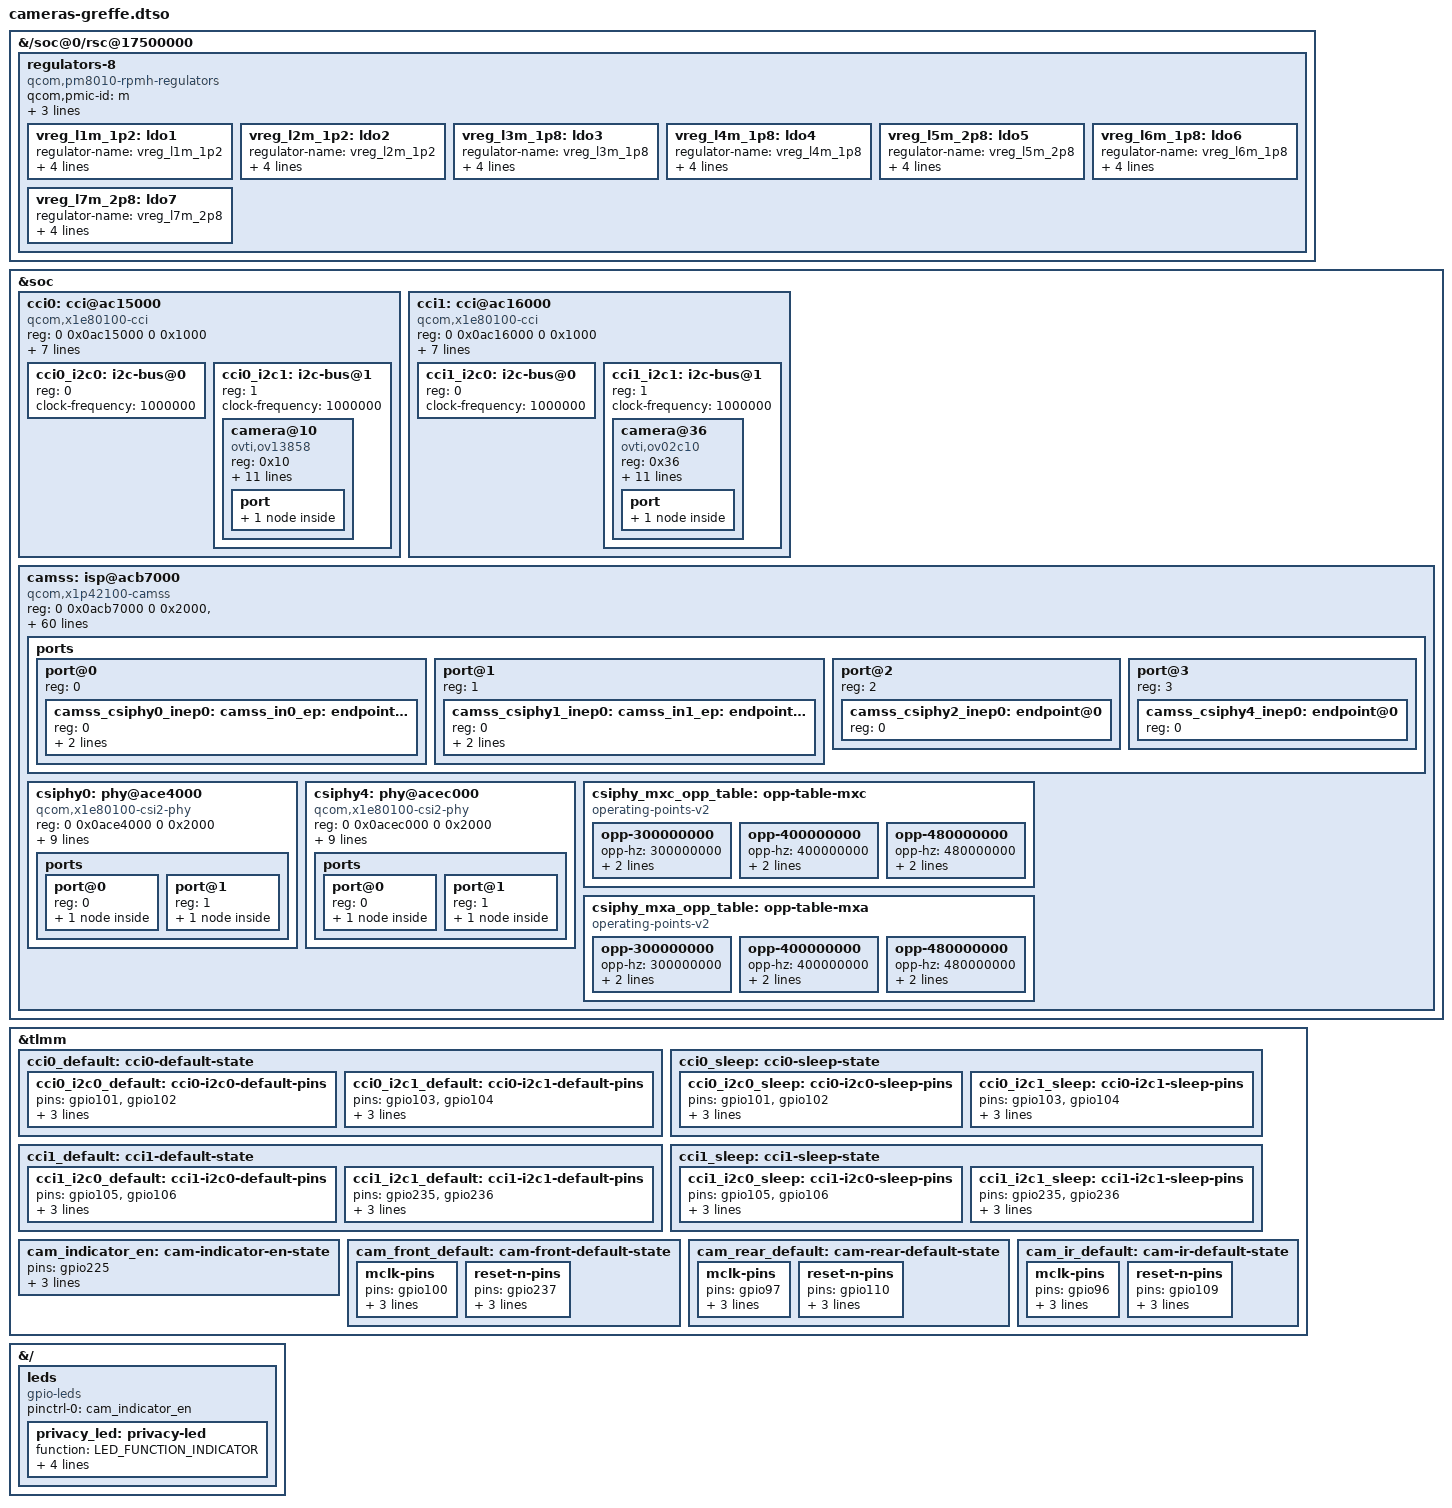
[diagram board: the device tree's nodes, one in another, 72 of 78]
/dts-v1/;
/plugin/;

/* Greffe caméra pour le DTB de juin (sp12-el2-pdc-test.dtb).
 * Fabriqué par systeme/bin/greffer-cameras.js — ne pas éditer à la main.
 * Les blocs sont découpés dans hamoa.dtsi et x1p42100-microsoft-sp12in.dts.
 */

#include <dt-bindings/clock/qcom,rpmh.h>
#include <dt-bindings/clock/qcom,sc8280xp-lpasscc.h>
#include <dt-bindings/clock/qcom,sm8450-videocc.h>
#include <dt-bindings/clock/qcom,x1e80100-camcc.h>
#include <dt-bindings/clock/qcom,x1e80100-dispcc.h>
#include <dt-bindings/clock/qcom,x1e80100-gcc.h>
#include <dt-bindings/clock/qcom,x1e80100-gpucc.h>
#include <dt-bindings/clock/qcom,x1e80100-tcsr.h>
#include <dt-bindings/clock/qcom,x1p42100-videocc.h>
#include <dt-bindings/dma/qcom-gpi.h>
#include <dt-bindings/firmware/qcom,scm.h>
#include <dt-bindings/gpio/gpio.h>
#include <dt-bindings/input/gpio-keys.h>
#include <dt-bindings/input/input.h>
#include <dt-bindings/interconnect/qcom,icc.h>
#include <dt-bindings/interconnect/qcom,x1e80100-rpmh.h>
#include <dt-bindings/interrupt-controller/arm-gic.h>
#include <dt-bindings/leds/common.h>
#include <dt-bindings/mailbox/qcom-ipcc.h>
#include <dt-bindings/media/video-interfaces.h>
#include <dt-bindings/phy/phy-qcom-qmp.h>
#include <dt-bindings/phy/phy.h>
#include <dt-bindings/pinctrl/qcom,pmic-gpio.h>
#include <dt-bindings/power/qcom,rpmhpd.h>
#include <dt-bindings/power/qcom-rpmpd.h>
#include <dt-bindings/regulator/qcom,rpmh-regulator.h>
#include <dt-bindings/soc/qcom,gpr.h>
#include <dt-bindings/soc/qcom,rpmh-rsc.h>
#include <dt-bindings/sound/qcom,q6dsp-lpass-ports.h>
#include <dt-bindings/thermal/thermal.h>

/* Le banc pm8010 : absent du DTB de juin, il alimente 7 des 11 rails des
 * capteurs. Ancré par chemin, faute de label rpmh_rsc dans __symbols__. */
&{/soc@0/rsc@17500000} {
	regulators-8 {
		compatible = "qcom,pm8010-rpmh-regulators";
		qcom,pmic-id = "m";

		vdd-l1-l2-supply = <&vreg_s5j_1p2>;
		vdd-l3-l4-supply = <&vreg_s4c_1p8>;
		vdd-l7-supply = <&vreg_bob1>;

		vreg_l1m_1p2: ldo1 {
			regulator-name = "vreg_l1m_1p2";
			regulator-min-microvolt = <1200000>;
			regulator-max-microvolt = <1260000>;
			regulator-initial-mode = <RPMH_REGULATOR_MODE_HPM>;
		};

		vreg_l2m_1p2: ldo2 {
			regulator-name = "vreg_l2m_1p2";
			regulator-min-microvolt = <1150000>;
			regulator-max-microvolt = <1200000>;
			regulator-initial-mode = <RPMH_REGULATOR_MODE_HPM>;
		};

		vreg_l3m_1p8: ldo3 {
			regulator-name = "vreg_l3m_1p8";
			regulator-min-microvolt = <1800000>;
			regulator-max-microvolt = <1800000>;
			regulator-initial-mode = <RPMH_REGULATOR_MODE_HPM>;
		};

		vreg_l4m_1p8: ldo4 {
			regulator-name = "vreg_l4m_1p8";
			regulator-min-microvolt = <1800000>;
			regulator-max-microvolt = <1800000>;
			regulator-initial-mode = <RPMH_REGULATOR_MODE_HPM>;
		};

		vreg_l5m_2p8: ldo5 {
			regulator-name = "vreg_l5m_2p8";
			regulator-min-microvolt = <2800000>;
			regulator-max-microvolt = <2800000>;
			regulator-initial-mode = <RPMH_REGULATOR_MODE_HPM>;
		};

		vreg_l6m_1p8: ldo6 {
			regulator-name = "vreg_l6m_1p8";
			regulator-min-microvolt = <1800000>;
			regulator-max-microvolt = <1800000>;
			regulator-initial-mode = <RPMH_REGULATOR_MODE_HPM>;
		};

		vreg_l7m_2p8: ldo7 {
			regulator-name = "vreg_l7m_2p8";
			regulator-min-microvolt = <2800000>;
			regulator-max-microvolt = <2800000>;
			regulator-initial-mode = <RPMH_REGULATOR_MODE_HPM>;
		};
	};
};

&soc {

	/* cci0 */
		cci0: cci@ac15000 {
			compatible = "qcom,x1e80100-cci", "qcom,msm8996-cci";
			reg = <0 0x0ac15000 0 0x1000>;

			interrupts = <GIC_SPI 460 IRQ_TYPE_EDGE_RISING>;

			clocks = <&camcc CAM_CC_CAMNOC_AXI_RT_CLK>,
				 <&camcc CAM_CC_CPAS_AHB_CLK>,
				 <&camcc CAM_CC_CCI_0_CLK>;
			clock-names = "camnoc_axi",
				      "cpas_ahb",
				      "cci";

			power-domains = <&camcc CAM_CC_TITAN_TOP_GDSC>;

			pinctrl-0 = <&cci0_default>;
			pinctrl-1 = <&cci0_sleep>;
			pinctrl-names = "default", "sleep";

			#address-cells = <1>;
			#size-cells = <0>;

			status = "disabled";

			cci0_i2c0: i2c-bus@0 {
				reg = <0>;
				clock-frequency = <1000000>;
				#address-cells = <1>;
				#size-cells = <0>;
			};

			cci0_i2c1: i2c-bus@1 {
				reg = <1>;
				clock-frequency = <1000000>;
				#address-cells = <1>;
				#size-cells = <0>;
			};
		};

	/* cci1 */
		cci1: cci@ac16000 {
			compatible = "qcom,x1e80100-cci", "qcom,msm8996-cci";
			reg = <0 0x0ac16000 0 0x1000>;

			interrupts = <GIC_SPI 271 IRQ_TYPE_EDGE_RISING>;

			clocks = <&camcc CAM_CC_CAMNOC_AXI_RT_CLK>,
				 <&camcc CAM_CC_CPAS_AHB_CLK>,
				 <&camcc CAM_CC_CCI_1_CLK>;
			clock-names = "camnoc_axi",
				      "cpas_ahb",
				      "cci";

			power-domains = <&camcc CAM_CC_TITAN_TOP_GDSC>;

			pinctrl-0 = <&cci1_default>;
			pinctrl-1 = <&cci1_sleep>;
			pinctrl-names = "default", "sleep";

			#address-cells = <1>;
			#size-cells = <0>;

			status = "disabled";

			cci1_i2c0: i2c-bus@0 {
				reg = <0>;
				clock-frequency = <1000000>;
				#address-cells = <1>;
				#size-cells = <0>;
			};

			cci1_i2c1: i2c-bus@1 {
				reg = <1>;
				clock-frequency = <1000000>;
				#address-cells = <1>;
				#size-cells = <0>;
			};
		};

	/* camss + csiphy0 + csiphy4 */
		camss: isp@acb7000 {
			compatible = "qcom,x1e80100-camss";

			reg = <0 0x0acb7000 0 0x2000>,
			      <0 0x0acb9000 0 0x2000>,
			      <0 0x0acbb000 0 0x2000>,
			      <0 0x0acc6000 0 0x1000>,
			      <0 0x0acca000 0 0x1000>,
			      <0 0x0acb6000 0 0x1000>,
			      <0 0x0ace4000 0 0x1000>,
			      <0 0x0ace6000 0 0x1000>,
			      <0 0x0ace8000 0 0x1000>,
			      <0 0x0acec000 0 0x4000>,
			      <0 0x0acf6000 0 0x1000>,
			      <0 0x0acf7000 0 0x1000>,
			      <0 0x0acf8000 0 0x1000>,
			      <0 0x0ac62000 0 0xf000>,
			      <0 0x0ac71000 0 0xf000>,
			      <0 0x0acc7000 0 0x2000>,
			      <0 0x0accb000 0 0x2000>;

			reg-names = "csid0",
				    "csid1",
				    "csid2",
				    "csid_lite0",
				    "csid_lite1",
				    "csid_wrapper",
				    "csiphy0",
				    "csiphy1",
				    "csiphy2",
				    "csiphy4",
				    "csitpg0",
				    "csitpg1",
				    "csitpg2",
				    "vfe0",
				    "vfe1",
				    "vfe_lite0",
				    "vfe_lite1";

			clocks = <&camcc CAM_CC_CAMNOC_AXI_NRT_CLK>,
				 <&camcc CAM_CC_CAMNOC_AXI_RT_CLK>,
				 <&camcc CAM_CC_CORE_AHB_CLK>,
				 <&camcc CAM_CC_CPAS_AHB_CLK>,
				 <&camcc CAM_CC_CPAS_FAST_AHB_CLK>,
				 <&camcc CAM_CC_CPAS_IFE_0_CLK>,
				 <&camcc CAM_CC_CPAS_IFE_1_CLK>,
				 <&camcc CAM_CC_CPAS_IFE_LITE_CLK>,
				 <&camcc CAM_CC_CPHY_RX_CLK_SRC>,
				 <&camcc CAM_CC_CSID_CLK>,
				 <&camcc CAM_CC_CSID_CSIPHY_RX_CLK>,
				 <&camcc CAM_CC_CSIPHY0_CLK>,
				 <&camcc CAM_CC_CSI0PHYTIMER_CLK>,
				 <&camcc CAM_CC_CSIPHY1_CLK>,
				 <&camcc CAM_CC_CSI1PHYTIMER_CLK>,
				 <&camcc CAM_CC_CSIPHY2_CLK>,
				 <&camcc CAM_CC_CSI2PHYTIMER_CLK>,
				 <&camcc CAM_CC_CSIPHY4_CLK>,
				 <&camcc CAM_CC_CSI4PHYTIMER_CLK>,
				 <&gcc GCC_CAMERA_HF_AXI_CLK>,
				 <&gcc GCC_CAMERA_SF_AXI_CLK>,
				 <&camcc CAM_CC_IFE_0_CLK>,
				 <&camcc CAM_CC_IFE_0_FAST_AHB_CLK>,
				 <&camcc CAM_CC_IFE_1_CLK>,
				 <&camcc CAM_CC_IFE_1_FAST_AHB_CLK>,
				 <&camcc CAM_CC_IFE_LITE_CLK>,
				 <&camcc CAM_CC_IFE_LITE_AHB_CLK>,
				 <&camcc CAM_CC_IFE_LITE_CPHY_RX_CLK>,
				 <&camcc CAM_CC_IFE_LITE_CSID_CLK>;

			clock-names = "camnoc_nrt_axi",
				      "camnoc_rt_axi",
				      "core_ahb",
				      "cpas_ahb",
				      "cpas_fast_ahb",
				      "cpas_vfe0",
				      "cpas_vfe1",
				      "cpas_vfe_lite",
				      "cphy_rx_clk_src",
				      "csid",
				      "csid_csiphy_rx",
				      "csiphy0",
				      "csiphy0_timer",
				      "csiphy1",
				      "csiphy1_timer",
				      "csiphy2",
				      "csiphy2_timer",
				      "csiphy4",
				      "csiphy4_timer",
				      "gcc_axi_hf",
				      "gcc_axi_sf",
				      "vfe0",
				      "vfe0_fast_ahb",
				      "vfe1",
				      "vfe1_fast_ahb",
				      "vfe_lite",
				      "vfe_lite_ahb",
				      "vfe_lite_cphy_rx",
				      "vfe_lite_csid";

			interrupts = <GIC_SPI 464 IRQ_TYPE_EDGE_RISING>,
				     <GIC_SPI 466 IRQ_TYPE_EDGE_RISING>,
				     <GIC_SPI 431 IRQ_TYPE_EDGE_RISING>,
				     <GIC_SPI 468 IRQ_TYPE_EDGE_RISING>,
				     <GIC_SPI 359 IRQ_TYPE_EDGE_RISING>,
				     <GIC_SPI 477 IRQ_TYPE_EDGE_RISING>,
				     <GIC_SPI 478 IRQ_TYPE_EDGE_RISING>,
				     <GIC_SPI 479 IRQ_TYPE_EDGE_RISING>,
				     <GIC_SPI 122 IRQ_TYPE_EDGE_RISING>,
				     <GIC_SPI 465 IRQ_TYPE_EDGE_RISING>,
				     <GIC_SPI 467 IRQ_TYPE_EDGE_RISING>,
				     <GIC_SPI 469 IRQ_TYPE_EDGE_RISING>,
				     <GIC_SPI 360 IRQ_TYPE_EDGE_RISING>;

			interrupt-names = "csid0",
					  "csid1",
					  "csid2",
					  "csid_lite0",
					  "csid_lite1",
					  "csiphy0",
					  "csiphy1",
					  "csiphy2",
					  "csiphy4",
					  "vfe0",
					  "vfe1",
					  "vfe_lite0",
					  "vfe_lite1";

			interconnects = <&gem_noc MASTER_APPSS_PROC QCOM_ICC_TAG_ACTIVE_ONLY
					 &config_noc SLAVE_CAMERA_CFG QCOM_ICC_TAG_ACTIVE_ONLY>,
					<&mmss_noc MASTER_CAMNOC_HF QCOM_ICC_TAG_ALWAYS
					 &mc_virt SLAVE_EBI1 QCOM_ICC_TAG_ALWAYS>,
					<&mmss_noc MASTER_CAMNOC_SF QCOM_ICC_TAG_ALWAYS
					 &mc_virt SLAVE_EBI1 QCOM_ICC_TAG_ALWAYS>,
					<&mmss_noc MASTER_CAMNOC_ICP QCOM_ICC_TAG_ALWAYS
					 &mc_virt SLAVE_EBI1 QCOM_ICC_TAG_ALWAYS>;
			interconnect-names = "ahb",
					     "hf_mnoc",
					     "sf_mnoc",
					     "sf_icp_mnoc";

			iommus = <&apps_smmu 0x800 0x60>,
				 <&apps_smmu 0x820 0x60>,
				 <&apps_smmu 0x840 0x60>,
				 <&apps_smmu 0x860 0x60>,
				 <&apps_smmu 0x18a0 0x0>;

			#address-cells = <2>;
			#size-cells = <2>;
			ranges;

			phys = <&csiphy0 PHY_TYPE_DPHY>,
			       <&csiphy1 PHY_TYPE_DPHY>,
			       <&csiphy2 PHY_TYPE_DPHY>,
			       <&csiphy4 PHY_TYPE_DPHY>;
			phy-names = "csiphy0",
				    "csiphy1",
				    "csiphy2",
				    "csiphy4";

			power-domains = <&camcc CAM_CC_IFE_0_GDSC>,
					<&camcc CAM_CC_IFE_1_GDSC>,
					<&camcc CAM_CC_TITAN_TOP_GDSC>;
			power-domain-names = "ife0",
					     "ife1",
					     "top";

			status = "disabled";

			ports {
				#address-cells = <1>;
				#size-cells = <0>;

				port@0 {
					reg = <0>;
					#address-cells = <1>;
					#size-cells = <0>;
					camss_csiphy0_inep0: endpoint@0 {
						reg = <0>;
					};
				};

				port@1 {
					reg = <1>;
					#address-cells = <1>;
					#size-cells = <0>;
					camss_csiphy1_inep0: endpoint@0 {
						reg = <0>;
					};
				};

				port@2 {
					reg = <2>;
					#address-cells = <1>;
					#size-cells = <0>;
					camss_csiphy2_inep0: endpoint@0 {
						reg = <0>;
					};
				};

				port@3 {
					reg = <3>;
					#address-cells = <1>;
					#size-cells = <0>;
					camss_csiphy4_inep0: endpoint@0 {
						reg = <0>;
					};
				};
			};

			csiphy0: phy@ace4000 {
				compatible = "qcom,x1e80100-csi2-phy";
				reg = <0 0x0ace4000 0 0x2000>;

				clocks = <&camcc CAM_CC_CSIPHY0_CLK>,
					 <&camcc CAM_CC_CSI0PHYTIMER_CLK>,
					 <&camcc CAM_CC_CORE_AHB_CLK>;
				clock-names = "core",
					      "timer",
					      "ahb";

				operating-points-v2 = <&csiphy_mxc_opp_table>;

				interrupts = <GIC_SPI 477 IRQ_TYPE_EDGE_RISING>;

				power-domains = <&camcc CAM_CC_TITAN_TOP_GDSC>,
						<&rpmhpd RPMHPD_MMCX>,
						<&rpmhpd RPMHPD_MXC>;
				power-domain-names = "top",
						     "mmcx",
						     "mx";

				#phy-cells = <1>;

				status = "disabled";
			};



			csiphy4: phy@acec000 {
				compatible = "qcom,x1e80100-csi2-phy";
				reg = <0 0x0acec000 0 0x2000>;

				clocks = <&camcc CAM_CC_CSIPHY4_CLK>,
					 <&camcc CAM_CC_CSI4PHYTIMER_CLK>,
					 <&camcc CAM_CC_CORE_AHB_CLK>;
				clock-names = "core",
					      "timer",
					      "ahb";

				operating-points-v2 = <&csiphy_mxa_opp_table>;

				interrupts = <GIC_SPI 122 IRQ_TYPE_EDGE_RISING>;

				power-domains = <&camcc CAM_CC_TITAN_TOP_GDSC>,
						<&rpmhpd RPMHPD_MMCX>,
						<&rpmhpd RPMHPD_MXC>;
				power-domain-names = "top",
						     "mmcx",
						     "mx";

				#phy-cells = <1>;

				status = "disabled";
			};

			csiphy_mxc_opp_table: opp-table-mxc {
				compatible = "operating-points-v2";

				opp-300000000 {
					opp-hz = /bits/ 64 <300000000>;
					required-opps = <&rpmhpd_opp_low_svs_d1>,
							<&rpmhpd_opp_low_svs_d1>;
				};

				opp-400000000 {
					opp-hz = /bits/ 64 <400000000>;
					required-opps = <&rpmhpd_opp_low_svs>,
							<&rpmhpd_opp_low_svs>;
				};

				opp-480000000 {
					opp-hz = /bits/ 64 <480000000>;
					required-opps = <&rpmhpd_opp_low_svs>,
							<&rpmhpd_opp_low_svs>;
				};
			};

			csiphy_mxa_opp_table: opp-table-mxa {
				compatible = "operating-points-v2";

				opp-300000000 {
					opp-hz = /bits/ 64 <300000000>;
					required-opps = <&rpmhpd_opp_low_svs_d1>,
							<&rpmhpd_opp_low_svs_d1>;
				};

				opp-400000000 {
					opp-hz = /bits/ 64 <400000000>;
					required-opps = <&rpmhpd_opp_low_svs>,
							<&rpmhpd_opp_low_svs_d1>;
				};

				opp-480000000 {
					opp-hz = /bits/ 64 <480000000>;
					required-opps = <&rpmhpd_opp_low_svs>,
							<&rpmhpd_opp_low_svs_d1>;
				};
			};
		};
};


/* x1p42100 (Purwa) : un seul IFE, autres horloges, autres IOMMU */
&camss {
	compatible = "qcom,x1p42100-camss";

	reg = <0 0x0acb7000 0 0x2000>,
	      <0 0x0acb9000 0 0x2000>,
	      <0 0x0acbb000 0 0x2000>,
	      <0 0x0acc6000 0 0x1000>,
	      <0 0x0acca000 0 0x1000>,
	      <0 0x0acb6000 0 0x1000>,
	      <0 0x0ace4000 0 0x1000>,
	      <0 0x0acec000 0 0x4000>,
	      <0 0x0acf6000 0 0x1000>,
	      <0 0x0acf7000 0 0x1000>,
	      <0 0x0acf8000 0 0x1000>,
	      <0 0x0ac62000 0 0x4000>,
	      <0 0x0acc7000 0 0x2000>,
	      <0 0x0accb000 0 0x2000>;

	reg-names = "csid0",
		    "csid1",
		    "csid2",
		    "csid_lite0",
		    "csid_lite1",
		    "csid_wrapper",
		    "csiphy0",
		    "csiphy4",
		    "csitpg0",
		    "csitpg1",
		    "csitpg2",
		    "vfe0",
		    "vfe_lite0",
		    "vfe_lite1";

	interrupts = <GIC_SPI 464 IRQ_TYPE_EDGE_RISING>,
		     <GIC_SPI 466 IRQ_TYPE_EDGE_RISING>,
		     <GIC_SPI 431 IRQ_TYPE_EDGE_RISING>,
		     <GIC_SPI 468 IRQ_TYPE_EDGE_RISING>,
		     <GIC_SPI 359 IRQ_TYPE_EDGE_RISING>,
		     <GIC_SPI 477 IRQ_TYPE_EDGE_RISING>,
		     <GIC_SPI 122 IRQ_TYPE_EDGE_RISING>,
		     <GIC_SPI 465 IRQ_TYPE_EDGE_RISING>,
		     <GIC_SPI 469 IRQ_TYPE_EDGE_RISING>,
		     <GIC_SPI 360 IRQ_TYPE_EDGE_RISING>;

	interrupt-names = "csid0",
			  "csid1",
			  "csid2",
			  "csid_lite0",
			  "csid_lite1",
			  "csiphy0",
			  "csiphy4",
			  "vfe0",
			  "vfe_lite0",
			  "vfe_lite1";

	clocks = <&camcc CAM_CC_CAMNOC_AXI_NRT_CLK>,
		 <&camcc CAM_CC_CAMNOC_AXI_RT_CLK>,
		 <&camcc CAM_CC_CORE_AHB_CLK>,
		 <&camcc CAM_CC_CPAS_AHB_CLK>,
		 <&camcc CAM_CC_CPAS_FAST_AHB_CLK>,
		 <&camcc CAM_CC_CPAS_IFE_0_CLK>,
		 <&camcc CAM_CC_CPAS_IFE_LITE_CLK>,
		 <&camcc CAM_CC_CPHY_RX_CLK_SRC>,
		 <&camcc CAM_CC_CSID_CLK>,
		 <&camcc CAM_CC_CSID_CSIPHY_RX_CLK>,
		 <&camcc CAM_CC_CSIPHY0_CLK>,
		 <&camcc CAM_CC_CSI0PHYTIMER_CLK>,
		 <&camcc CAM_CC_CSIPHY4_CLK>,
		 <&camcc CAM_CC_CSI4PHYTIMER_CLK>,
		 <&gcc GCC_CAMERA_HF_AXI_CLK>,
		 <&gcc GCC_CAMERA_SF_AXI_CLK>,
		 <&camcc CAM_CC_IFE_0_CLK>,
		 <&camcc CAM_CC_IFE_0_FAST_AHB_CLK>,
		 <&camcc CAM_CC_IFE_LITE_CLK>,
		 <&camcc CAM_CC_IFE_LITE_AHB_CLK>,
		 <&camcc CAM_CC_IFE_LITE_CPHY_RX_CLK>,
		 <&camcc CAM_CC_IFE_LITE_CSID_CLK>;

	clock-names = "camnoc_nrt_axi",
		      "camnoc_rt_axi",
		      "core_ahb",
		      "cpas_ahb",
		      "cpas_fast_ahb",
		      "cpas_vfe0",
		      "cpas_vfe_lite",
		      "cphy_rx_clk_src",
		      "csid",
		      "csid_csiphy_rx",
		      "csiphy0",
		      "csiphy0_timer",
		      "csiphy4",
		      "csiphy4_timer",
		      "gcc_axi_hf",
		      "gcc_axi_sf",
		      "vfe0",
		      "vfe0_fast_ahb",
		      "vfe_lite",
		      "vfe_lite_ahb",
		      "vfe_lite_cphy_rx",
		      "vfe_lite_csid";

	interconnects = <&gem_noc MASTER_APPSS_PROC QCOM_ICC_TAG_ACTIVE_ONLY
			 &config_noc SLAVE_CAMERA_CFG QCOM_ICC_TAG_ACTIVE_ONLY>,
			<&mmss_noc MASTER_CAMNOC_HF QCOM_ICC_TAG_ALWAYS
			 &mc_virt SLAVE_EBI1 QCOM_ICC_TAG_ALWAYS>,
			<&mmss_noc MASTER_CAMNOC_SF QCOM_ICC_TAG_ALWAYS
			 &mc_virt SLAVE_EBI1 QCOM_ICC_TAG_ALWAYS>,
			<&mmss_noc MASTER_CAMNOC_ICP QCOM_ICC_TAG_ALWAYS
			 &mc_virt SLAVE_EBI1 QCOM_ICC_TAG_ALWAYS>;
	interconnect-names = "ahb",
			     "hf_mnoc",
			     "sf_mnoc",
			     "sf_icp_mnoc";

	iommus = <&apps_smmu 0x800 0x60>,
		 <&apps_smmu 0x860 0x60>,
		 <&apps_smmu 0x1860 0x60>,
		 <&apps_smmu 0x18e0 0x00>,
		 <&apps_smmu 0x19a0 0x20>;

	power-domains = <&camcc CAM_CC_IFE_0_GDSC>,
			<&camcc CAM_CC_TITAN_TOP_GDSC>;
	power-domain-names = "ife0",
			     "top";

	phys = <&csiphy0 PHY_TYPE_DPHY>,
	       <&csiphy4 PHY_TYPE_DPHY>;
	phy-names = "csiphy0",
		    "csiphy4";

	status = "disabled";

	ports {
		#address-cells = <1>;
		#size-cells = <0>;

		port@0 {
			reg = <0>;
			#address-cells = <1>;
			#size-cells = <0>;
			camss_in0_ep: endpoint@0 {
				reg = <0>;
			};
		};

		port@1 {
			reg = <1>;
			#address-cells = <1>;
			#size-cells = <0>;
			camss_in1_ep: endpoint@0 {
				reg = <0>;
			};
		};
	};
};

&tlmm {

	/* cci0_default */
			cci0_default: cci0-default-state {
				cci0_i2c0_default: cci0-i2c0-default-pins {
					/* cci_i2c_sda0, cci_i2c_scl0 */
					pins = "gpio101", "gpio102";
					function = "cci_i2c";
					drive-strength = <2>;
					bias-pull-up;
				};

				cci0_i2c1_default: cci0-i2c1-default-pins {
					/* cci_i2c_sda1, cci_i2c_scl1 */
					pins = "gpio103", "gpio104";
					function = "cci_i2c";
					drive-strength = <2>;
					bias-pull-up;
				};
			};

	/* cci0_sleep */
			cci0_sleep: cci0-sleep-state {
				cci0_i2c0_sleep: cci0-i2c0-sleep-pins {
					/* cci_i2c_sda0, cci_i2c_scl0 */
					pins = "gpio101", "gpio102";
					function = "cci_i2c";
					drive-strength = <2>;
					bias-pull-down;
				};

				cci0_i2c1_sleep: cci0-i2c1-sleep-pins {
					/* cci_i2c_sda1, cci_i2c_scl1 */
					pins = "gpio103", "gpio104";
					function = "cci_i2c";
					drive-strength = <2>;
					bias-pull-down;
				};
			};

	/* cci1_default */
			cci1_default: cci1-default-state {
				cci1_i2c0_default: cci1-i2c0-default-pins {
					/* cci_i2c_sda2, cci_i2c_scl2 */
					pins = "gpio105", "gpio106";
					function = "cci_i2c";
					drive-strength = <2>;
					bias-pull-up;
				};

				cci1_i2c1_default: cci1-i2c1-default-pins {
					/* aon_cci_i2c_sda3, aon_cci_i2c_scl3 */
					pins = "gpio235", "gpio236";
					function = "aon_cci";
					drive-strength = <2>;
					bias-pull-up;
				};
			};

	/* cci1_sleep */
			cci1_sleep: cci1-sleep-state {
				cci1_i2c0_sleep: cci1-i2c0-sleep-pins {
					/* cci_i2c_sda2, cci_i2c_scl2 */
					pins = "gpio105", "gpio106";
					function = "cci_i2c";
					drive-strength = <2>;
					bias-pull-down;
				};

				cci1_i2c1_sleep: cci1-i2c1-sleep-pins {
					/* aon_cci_i2c_sda3, aon_cci_i2c_scl3 */
					pins = "gpio235", "gpio236";
					function = "aon_cci";
					drive-strength = <2>;
					bias-pull-down;
				};
			};

	/* cam_indicator_en */
	cam_indicator_en: cam-indicator-en-state {
		pins = "gpio225";
		function = "gpio";
		drive-strength = <2>;
		bias-disable;
	};

	/* cam_front_default */
	cam_front_default: cam-front-default-state {
		mclk-pins {
			pins = "gpio100";
			function = "cam_aon";
			drive-strength = <16>;
			bias-disable;
		};

		reset-n-pins {
			pins = "gpio237";
			function = "gpio";
			drive-strength = <2>;
			bias-disable;
		};
	};

	/* cam_rear_default */
	cam_rear_default: cam-rear-default-state {
		mclk-pins {
			pins = "gpio97";
			function = "cam_mclk";
			drive-strength = <16>;
			bias-disable;
		};

		reset-n-pins {
			pins = "gpio110";
			function = "gpio";
			drive-strength = <2>;
			bias-disable;
		};
	};

	/* cam_ir_default */
	cam_ir_default: cam-ir-default-state {
		mclk-pins {
			pins = "gpio96";
			function = "cam_mclk";
			drive-strength = <16>;
			bias-disable;
		};

		reset-n-pins {
			pins = "gpio109";
			function = "gpio";
			drive-strength = <2>;
			bias-disable;
		};
	};
};

/* leds (témoin de confidentialité) */
&{/} {
	leds {
		compatible = "gpio-leds";

		pinctrl-0 = <&cam_indicator_en>;
		pinctrl-names = "default";

		privacy_led: privacy-led {
			function = LED_FUNCTION_INDICATOR;
			color = <LED_COLOR_ID_WHITE>;
			gpios = <&tlmm 225 GPIO_ACTIVE_HIGH>;
			default-state = "off";
			panic-indicator;
		};
	};
};

/* &camss */
&camss {
	status = "okay";

	ports {
		/*
		 * port0 => csiphy0
		 * port1 => csiphy4
		 */
		port@0 {
			camss_csiphy0_inep: endpoint@0 {
				reg = <0>;
				data-lanes = <0 1 2 3>;  /* recepteur : numerotation a partir de 0 */
				remote-endpoint = <&csiphy0_out_ep>;
			};
		};

		port@1 {
			camss_csiphy4_inep: endpoint@0 {
				reg = <0>;
				data-lanes = <0 1>;  /* recepteur : numerotation a partir de 0 */
				remote-endpoint = <&csiphy4_out_ep>;
			};
		};
	};
};

/* &cci0 */
&cci0 {
	status = "okay";
};

/* &cci1 */
&cci1 {
	status = "okay";
};

/* &cci0_i2c1 — capteur arrière ov13858 */
&cci0_i2c1 {
	camera@10 {
		compatible = "ovti,ov13858";
		reg = <0x10>;

		reset-gpios = <&tlmm 110 GPIO_ACTIVE_LOW>;
		pinctrl-names = "default";
		pinctrl-0 = <&cam_rear_default>;

		clocks = <&camcc CAM_CC_MCLK1_CLK>;
		assigned-clocks = <&camcc CAM_CC_MCLK1_CLK>;
		assigned-clock-rates = <19200000>;

		rotation = <180>;
		orientation = <1>;

		afvdd-supply = <&vreg_l16b_2p9>;
		avdd-supply = <&vreg_l5m_2p8>;
		dvdd-supply = <&vreg_l1m_1p2>;
		dovdd-supply = <&vreg_l6m_1p8>;

		port {
			ov13858_ep: endpoint {
				data-lanes = <1 2 3 4>;
				link-frequencies = /bits/ 64 <540000000 270000000>;
				remote-endpoint = <&csiphy0_in_ep>;
			};
		};
	};
};

/* &cci1_i2c1 — capteur avant ov02c10 */
&cci1_i2c1 {
	camera@36 {
		compatible = "ovti,ov02c10";
		reg = <0x36>;

		reset-gpios = <&tlmm 237 GPIO_ACTIVE_LOW>;
		pinctrl-names = "default";
		pinctrl-0 = <&cam_front_default>;

		leds = <&privacy_led>;
		led-names = "privacy";

		clocks = <&camcc CAM_CC_MCLK4_CLK>;
		assigned-clocks = <&camcc CAM_CC_MCLK4_CLK>;
		assigned-clock-rates = <12000000>;

		orientation = <0>;

		avdd-supply = <&vreg_l7b_2p8>;
		dvdd-supply = <&vreg_l7b_2p8>;
		dovdd-supply = <&vreg_l3m_1p8>;

		port {
			ov02c10_ep: endpoint {
				data-lanes = <1 2>;
				link-frequencies = /bits/ 64 <400000000>;
				remote-endpoint = <&csiphy4_in_ep0>;
			};
		};
	};
};

/* &csiphy0 */
&csiphy0 {
	vdda-0p9-supply = <&vreg_l2c_0p8>;
	vdda-1p2-supply = <&vreg_l1c_1p2>;

	status = "okay";


	ports {
		#address-cells = <1>;
		#size-cells = <0>;

		port@0 {
			reg = <0>;

			csiphy0_in_ep: endpoint {
				bus-type = <MEDIA_BUS_TYPE_CSI2_DPHY>;
				clock-lanes = <0>;
				data-lanes = <0 1 2 3>;  /* recepteur : numerotation a partir de 0 */
				remote-endpoint = <&ov13858_ep>;
			};
		};

		port@1 {
			reg = <1>;

			csiphy0_out_ep: endpoint {
				remote-endpoint = <&camss_csiphy0_inep>;
			};
		};
	};
};

/* &csiphy4 */
&csiphy4 {
	vdda-0p9-supply = <&vreg_l2c_0p8>;
	vdda-1p2-supply = <&vreg_l1c_1p2>;

	status = "okay";

	ports {
		#address-cells = <1>;
		#size-cells = <0>;

		port@0 {
			reg = <0>;

			csiphy4_in_ep0: endpoint {
				bus-type = <MEDIA_BUS_TYPE_CSI2_DPHY>;
				clock-lanes = <0>;
				data-lanes = <0 1>;  /* recepteur : numerotation a partir de 0 */
				remote-endpoint = <&ov02c10_ep>;
			};

			/*csiphy4_in_ep1: endpoint@1 {
				data-lanes = <1>;
				clock-lanes = <3>;
				remote-endpoint = <&vd55g1_ep>;
			};*/
		};

		port@1 {
			reg = <1>;

			csiphy4_out_ep: endpoint {
				remote-endpoint = <&camss_csiphy4_inep>;
			};
		};
	};
};
